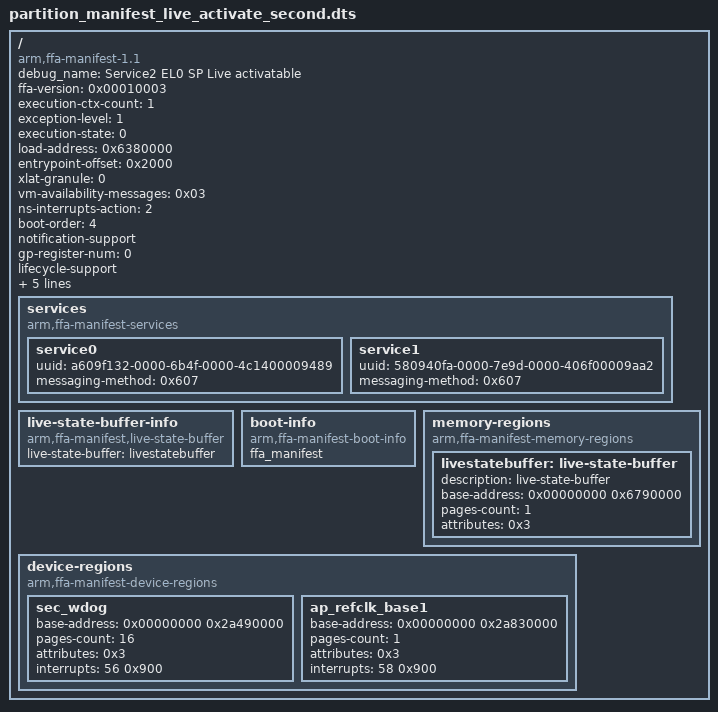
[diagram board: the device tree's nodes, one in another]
/*
 * Copyright 2026 The Hafnium Authors.
 *
 * Use of this source code is governed by a BSD-style
 * license that can be found in the LICENSE file or at
 * https://opensource.org/licenses/BSD-3-Clause.
 */

/dts-v1/;

/ {
	compatible = "arm,ffa-manifest-1.1";
	debug_name = "Service2 EL0 SP Live activatable";

	/* Properties */
	ffa-version = <0x00010003>; /* 31:16 - Major, 15:0 - Minor */
	execution-ctx-count = <1>;
	exception-level = <1>; /* S-EL0 */
	execution-state = <0>; /* AARCH64 */
	load-address = <0x6380000>;
	entrypoint-offset = <0x2000>;
	xlat-granule = <0>; /* 4KiB */
	vm-availability-messages = <0x03>; /* Supports VM created and VM destroyed messages. */
	ns-interrupts-action = <2>; /* NS interrupts are signaled */
	boot-order = <4>;
	notification-support; /* Receipt of notifications. */
	gp-register-num = <0>;

	/* Lifecycle support and Live activation fields. */
	lifecycle-support;
	abort-action = <1>; /* Destroy */
	live-activation-support;
	live-activation-register = <1>;

	image-uuid = "2721ffc3-f8a9-417e-a124-af057434a3af";

	services {
		compatible = "arm,ffa-manifest-services";

		service0 {
			uuid = "a609f132-0000-6b4f-0000-4c1400009489";
			messaging-method = <0x607>; /* Support direct (both APIs) and indirect messaging. */
		};

		service1 {
			uuid = "580940fa-0000-7e9d-0000-406f00009aa2"; /* EL0 service uuid. */
			messaging-method = <0x607>; /* Support direct (both APIs) and indirect messaging. */
		};
	};

	live-state-buffer-info {
		compatible = "arm,ffa-manifest,live-state-buffer";
		live-state-buffer = <&livestatebuffer>;
	};

	/* Boot Info */
	boot-info {
		compatible = "arm,ffa-manifest-boot-info";
		ffa_manifest;
	};

	memory-regions {

		compatible = "arm,ffa-manifest-memory-regions";

		livestatebuffer: live-state-buffer {
			description = "live-state-buffer";
			base-address = <0x00000000 0x6790000>;
			pages-count = <1>;
			attributes = <0x3>; /* read-write */
		};
	};

	device-regions {
		compatible = "arm,ffa-manifest-device-regions";

		sec_wdog {
			/* SP805 Trusted Watchdog Module */
			base-address = <0x00000000 0x2a490000>;
			pages-count = <16>; /* One 64KB page */
			attributes = <0x3>; /* read-write */
			interrupts = <56 0x900>;
		};

		ap_refclk_base1 {
			/* AP_REFCLK Generic System timer */
			base-address = <0x00000000 0x2a830000>;
			pages-count = <1>; /* One 4KB page */
			attributes = <0x3>; /* read-write */
			interrupts = <58 0x900>;
		};
	};
};
